# ATmega162 device description
Architecture: AVR8; Family: megaAVR
Programming and debug interfaces: ISP, HVPP, JTAG
Registers are 8-bit, access not given, no defined reset value unless marked. A register's access mark holds for its fields unless they carry their own. Offsets are from the block's base; lines under a group give offsets from that group; [hi:lo] are bit positions; {n}, {i} and the like mark numbered series; 'fields as' and 'values as' point back to an identical list; <NAME> marks a mode.

## Ordering variants
standard: 1.8 to 5.5 V

## Memory
prog space: start 0x0000 size 0x4000, little endian
  0x0000 FLASH size 0x4000 flash, rw, executable, page 0x80
  0x3f00 BOOT_SECTION_1 size 0x0100 flash, rw, executable, page 0x80
  0x3e00 BOOT_SECTION_2 size 0x0200 flash, rw, executable, page 0x80
  0x3c00 BOOT_SECTION_3 size 0x0400 flash, rw, executable, page 0x80
  0x3800 BOOT_SECTION_4 size 0x0800 flash, rw, executable, page 0x80
signatures space: start 0 size 3, little endian
  0 SIGNATURES size 3 signatures, ro
fuses space: start 0 size 0x0003, little endian
  0 FUSES size 0x0003 fuses, rw
lockbits space: start 0 size 0x0001, little endian
  0 LOCKBITS size 0x0001 lockbits, rw
data space: start 0x0000 size 0x10000, little endian
  0x0000 REGISTERS size 0x0020 regs
  0x0020 MAPPED_IO size 0x00e0 io
  0x0100 IRAM size 0x0400 ram
  0x0500 XRAM size 0xfb00 ram, external
eeprom space: start 0x0000 size 0x0200, little endian
  0x0000 EEPROM size 0x0200 eeprom, rw, page 0x04
io space: start 0x00 size 0x40, little endian
osccal space: start 0 size 1, little endian
  0 OSCCAL size 1 osccal, ro

## Peripheral instances (address, pins/pin function, parameters)
TC1 at 0x00 — Timer/Counter, 16-bit
TC3 at 0x00 — Timer/Counter, 16-bit
TC2 at 0x00 — Timer/Counter, 8-bit Async
AC at 0x00 — Analog Comparator
USART0 at 0x00 — USART
USART1 at 0x00 — USART
SPI at 0x00 — Serial Peripheral Interface
CPU at 0x00 — CPU Registers
JTAG at 0x00 — JTAG Interface
BOOT_LOAD at 0x00 — Bootloader
EEPROM at 0x00
PORTA at 0x00 — I/O Port
PORTB at 0x00 — I/O Port
PORTC at 0x00 — I/O Port
PORTD at 0x00 — I/O Port
PORTE at 0x00 — I/O Port
TC0 at 0x00 — Timer/Counter, 8-bit
WDT at 0x00 — Watchdog Timer
EXINT at 0x00 — External Interrupts
FUSE at 0 in fuses — Fuses
LOCKBIT at 0 in lockbits — Lockbits

## Interrupts
0 RESET — External Pin,Power-on Reset,Brown-out Reset,Watchdog Reset,and JTAG AVR Reset. See Datasheet.
1 INT0 — External Interrupt Request 0
2 INT1 — External Interrupt Request 1
3 INT2 — External Interrupt Request 2
4 PCINT0 — Pin Change Interrupt Request 0
5 PCINT1 — Pin Change Interrupt Request 1
6 TIMER3_CAPT — Timer/Counter3 Capture Event
7 TIMER3_COMPA — Timer/Counter3 Compare Match A
8 TIMER3_COMPB — Timer/Counter3 Compare Match B
9 TIMER3_OVF — Timer/Counter3 Overflow
10 TIMER2_COMP — Timer/Counter2 Compare Match
11 TIMER2_OVF — Timer/Counter2 Overflow
12 TIMER1_CAPT — Timer/Counter1 Capture Event
13 TIMER1_COMPA — Timer/Counter1 Compare Match A
14 TIMER1_COMPB — Timer/Counter Compare Match B
15 TIMER1_OVF — Timer/Counter1 Overflow
16 TIMER0_COMP — Timer/Counter0 Compare Match
17 TIMER0_OVF — Timer/Counter0 Overflow
18 SPI_STC — SPI Serial Transfer Complete
19 USART0_RXC — USART0, Rx Complete
20 USART1_RXC — USART1, Rx Complete
21 USART0_UDRE — USART0 Data register Empty
22 USART1_UDRE — USART1, Data register Empty
23 USART0_TXC — USART0, Tx Complete
24 USART1_TXC — USART1, Tx Complete
25 EE_RDY — EEPROM Ready
26 ANA_COMP — Analog Comparator
27 SPM_RDY — Store Program Memory Read

## Properties
SIGNATURES: JTAGID=0x0940403F, SIGNATURE0=0x1e, SIGNATURE1=0x94, SIGNATURE2=0x04
OCD: OCD_REVISION=2, OCD_DATAREG=0x04, PROGBASE=0x0000

## LOCKBIT — Lockbits
Instances: LOCKBIT 0 in lockbits
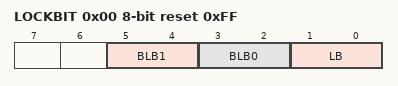
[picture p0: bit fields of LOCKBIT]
0x00 LOCKBIT reset 0xFF
  [5:4] BLB1 — Boot Loader Protection Mode
    0=LPM_SPM_DISABLE (LPM and SPM prohibited in Boot Section); 1=LPM_DISABLE (LPM prohibited in Boot Section); 2=SPM_DISABLE (SPM prohibited in Boot Section); 3=NO_LOCK (No lock on SPM and LPM in Boot Section)
  [3:2] BLB0 — Boot Loader Protection Mode
    0=LPM_SPM_DISABLE (LPM and SPM prohibited in Application Section); 1=LPM_DISABLE (LPM prohibited in Application Section); 2=SPM_DISABLE (SPM prohibited in Application Section); 3=NO_LOCK (No lock on SPM and LPM in Application Section)
  [1:0] LB — Memory Lock
    0=PROG_VER_DISABLED (Further programming and verification disabled); 2=PROG_DISABLED (Further programming disabled); 3=NO_LOCK (No memory lock features enabled)
